AUTOSAR XML (schema 00051)
package /TPC_Composition/Components
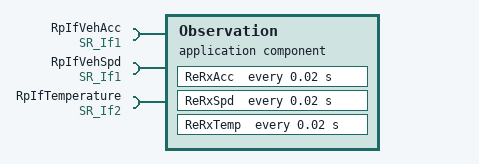
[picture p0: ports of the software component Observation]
  application sw component type Observation
    require port RpIfVehAcc: required-interface=SR_If1, nonqueued-receiver-com-spec{data-element=Acc, init-value=111}
    require port RpIfVehSpd: required-interface=SR_If1, nonqueued-receiver-com-spec{data-element=Spd, init-value=111}
    require port RpIfTemperature: required-interface=SR_If2, queued-receiver-com-spec{data-element=Temp, queue-length=10}
    behavior SWC_Observation_InternalBehavior
      runnable ReRxAcc
        data-receive-point-by-arguments:
          access DataReceivePointByArgument_PpIfVehMov_Acc: return-value-provision=RETURN-VALUE-PROVIDED, accessed-variable=RpIfVehAcc.Acc
      runnable ReRxSpd
        data-receive-point-by-values:
          access DataReceivePointByValue_PpIfVehMov_Spd: accessed-variable=RpIfVehSpd.Spd
      runnable ReRxTemp
        data-receive-point-by-arguments:
          access DataReceivePointByValue_PpIfTemperature_Temp: return-value-provision=RETURN-VALUE-PROVIDED, accessed-variable=RpIfTemperature.Temp
        wait point ReRxTemp_WaitPoint: timeout=0.01, trigger=Obv_Ev_DR
      timing event EvTiAcc_20ms: start-on-event=ReRxAcc, period=0.02
      timing event EvTiSpd_20ms: start-on-event=ReRxSpd, period=0.02
      timing event EvTiTemp_20ms: start-on-event=ReRxTemp, period=0.02
      data received event Obv_Ev_DR: data=RpIfTemperature.Temp
      port-api-options:
        port=RpIfVehAcc, transformer-status-forwarding=TRANSFORMER-STATUS-FORWARDING, error-handling=TRANSFORMER-ERROR-HANDLING
        port=RpIfVehSpd, error-handling=NO-TRANSFORMER-ERROR-HANDLING
        port=RpIfTemperature, error-handling=TRANSFORMER-ERROR-HANDLING
